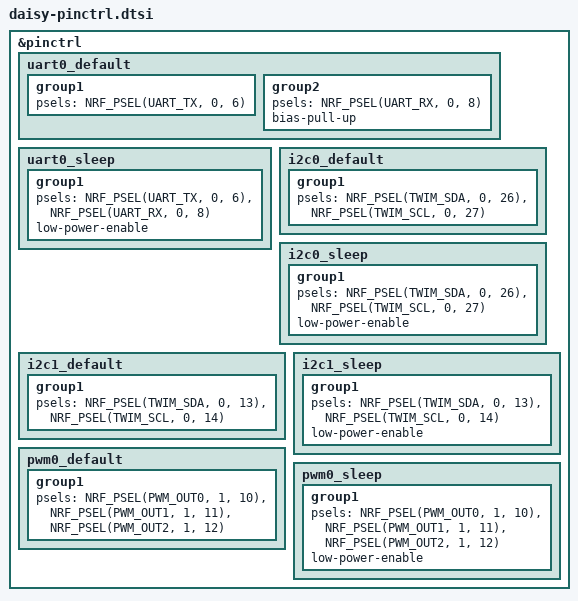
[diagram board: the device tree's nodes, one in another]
/*
 * Copyright (c) 2025 Framework Computer Inc
 * SPDX-License-Identifier: Apache-2.0
 */

&pinctrl {
	uart0_default: uart0_default {
		group1 {
			psels = <NRF_PSEL(UART_TX, 0, 6)>;
		};
		group2 {
			psels = <NRF_PSEL(UART_RX, 0, 8)>;
			bias-pull-up;
		};
	};

	uart0_sleep: uart0_sleep {
		group1 {
			psels = <NRF_PSEL(UART_TX, 0, 6)>,
				<NRF_PSEL(UART_RX, 0, 8)>;
			low-power-enable;
		};
	};

	i2c0_default: i2c0_default {
		group1 {
			psels = <NRF_PSEL(TWIM_SDA, 0, 26)>,
				<NRF_PSEL(TWIM_SCL, 0, 27)>;
		};
	};

	i2c0_sleep: i2c0_sleep {
		group1 {
			psels = <NRF_PSEL(TWIM_SDA, 0, 26)>,
				<NRF_PSEL(TWIM_SCL, 0, 27)>;
			low-power-enable;
		};
	};

	i2c1_default: i2c1_default {
		group1 {
			psels = <NRF_PSEL(TWIM_SDA, 0, 13)>,
				<NRF_PSEL(TWIM_SCL, 0, 14)>;
		};
	};

	i2c1_sleep: i2c1_sleep {
		group1 {
			psels = <NRF_PSEL(TWIM_SDA, 0, 13)>,
				<NRF_PSEL(TWIM_SCL, 0, 14)>;
			low-power-enable;
		};
	};

	pwm0_default: pwm0_default {
		group1 {
			psels
				= <NRF_PSEL(PWM_OUT0, 1, 10)>
				, <NRF_PSEL(PWM_OUT1, 1, 11)>
				, <NRF_PSEL(PWM_OUT2, 1, 12)>
				;
		};
	};

	pwm0_sleep: pwm0_sleep {
		group1 {
			psels
				= <NRF_PSEL(PWM_OUT0, 1, 10)>
				, <NRF_PSEL(PWM_OUT1, 1, 11)>
				, <NRF_PSEL(PWM_OUT2, 1, 12)>
				;
			low-power-enable;
		};
	};
};
